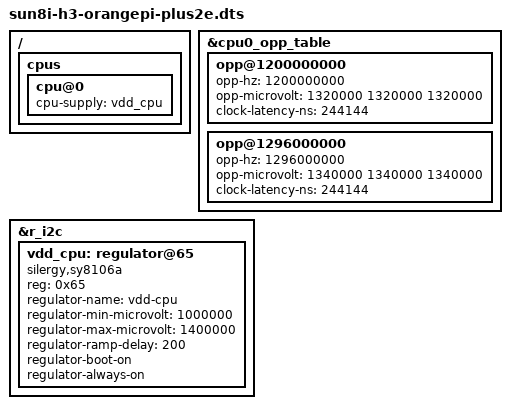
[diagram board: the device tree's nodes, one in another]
/* $NetBSD: sun8i-h3-orangepi-plus2e.dts,v 1.4.28.1 2023/09/13 09:42:50 martin Exp $ */

/*-
 * Copyright (c) 2017 Jared McNeill <jmcneill@invisible.ca>
 * All rights reserved.
 *
 * Redistribution and use in source and binary forms, with or without
 * modification, are permitted provided that the following conditions
 * are met:
 * 1. Redistributions of source code must retain the above copyright
 *    notice, this list of conditions and the following disclaimer.
 * 2. Redistributions in binary form must reproduce the above copyright
 *    notice, this list of conditions and the following disclaimer in the
 *    documentation and/or other materials provided with the distribution.
 *
 * THIS SOFTWARE IS PROVIDED BY THE AUTHOR ``AS IS'' AND ANY EXPRESS OR
 * IMPLIED WARRANTIES, INCLUDING, BUT NOT LIMITED TO, THE IMPLIED WARRANTIES
 * OF MERCHANTABILITY AND FITNESS FOR A PARTICULAR PURPOSE ARE DISCLAIMED.
 * IN NO EVENT SHALL THE AUTHOR BE LIABLE FOR ANY DIRECT, INDIRECT,
 * INCIDENTAL, SPECIAL, EXEMPLARY, OR CONSEQUENTIAL DAMAGES (INCLUDING,
 * BUT NOT LIMITED TO, PROCUREMENT OF SUBSTITUTE GOODS OR SERVICES;
 * LOSS OF USE, DATA, OR PROFITS; OR BUSINESS INTERRUPTION) HOWEVER CAUSED
 * AND ON ANY THEORY OF LIABILITY, WHETHER IN CONTRACT, STRICT LIABILITY,
 * OR TORT (INCLUDING NEGLIGENCE OR OTHERWISE) ARISING IN ANY WAY
 * OUT OF THE USE OF THIS SOFTWARE, EVEN IF ADVISED OF THE POSSIBILITY OF
 * SUCH DAMAGE.
 */

#include "../../../external/gpl2/dts/dist/arch/arm/boot/dts/sun8i-h3-orangepi-plus2e.dts"

/ {
	cpus {
		cpu@0 {
			cpu-supply = <&vdd_cpu>;
		};
	};
};

&cpu0_opp_table {
	opp@1200000000 {
		opp-hz = /bits/ 64 <1200000000>;
		opp-microvolt = <1320000 1320000 1320000>;
		clock-latency-ns = <244144>;
	};

	opp@1296000000 {
		opp-hz = /bits/ 64 <1296000000>;
		opp-microvolt = <1340000 1340000 1340000>;
		clock-latency-ns = <244144>;
	};
};

&r_i2c {
	status = "okay";

	vdd_cpu: regulator@65 {
		compatible = "silergy,sy8106a";
		reg = <0x65>;

		regulator-name = "vdd-cpu";
		regulator-min-microvolt = <1000000>;
		regulator-max-microvolt = <1400000>;
		regulator-ramp-delay = <200>;
		regulator-boot-on;
		regulator-always-on;
	};
};
